# STM32WL33 register map
File version: 1.2
CPU: CM0+ r0p0, little endian, MPU, no FPU, 4 interrupt priority bits
Registers are 32-bit, read-write, reset 0x0 unless marked. A register's access mark holds for its fields unless they carry their own. Offsets are from the block's base; [hi:lo] are bit positions.

## STATUS
Base 0x49000600
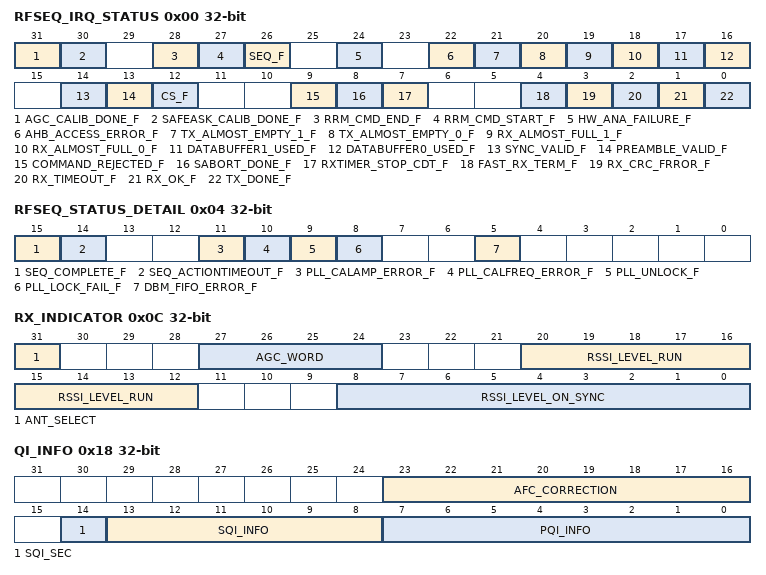
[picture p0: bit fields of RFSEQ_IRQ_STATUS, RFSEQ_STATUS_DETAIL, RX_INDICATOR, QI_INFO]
0x00 RFSEQ_IRQ_STATUS
  [31] AGC_CALIB_DONE_F — Valid RSSI value available in the RSSI_RUNNING bit field flag.
  [30] SAFEASK_CALIB_DONE_F — End of Safe-ASK PA calibration flag.
  [28] RRM_CMD_END_F — RRM-UDRA command list execution ended flag.
  [27] RRM_CMD_START_F — RRM-UDRA command list execution started flag.
  [26] SEQ_F — Sequencer completion flag.
  [24] HW_ANA_FAILURE_F — Analog HW failure flag (PLL lock / unlock error, calibration error)
  [22] AHB_ACCESS_ERROR_F — An AHB transfer issue occurred for one of the AHB masters (RRM, Data Buffer Manager, Sequencer).
  [21] TX_ALMOST_EMPTY_1_F — Data Buffer1 used (read during a TX) up to programmed thresold flag
  [20] TX_ALMOST_EMPTY_0_F — Data Buffer0 used (read during a TX) up to programmed thresold flag
  [19] RX_ALMOST_FULL_1_F — Data Buffer1 used (written during a RX) up to programmed thresold flag
  [18] RX_ALMOST_FULL_0_F — Data Buffer0 used (written during a RX) up to programmed thresold flag
  [17] DATABUFFER1_USED_F — Data Buffer 1 fully read in TX or fully written in RX flag
  [16] DATABUFFER0_USED_F — Data Buffer 0 fully read in TX or fully written in RX flag
  [14] SYNC_VALID_F — Valid SYNC word detection flag.
  [13] PREAMBLE_VALID_F — Valid PREAMBLE detection flag.
  [12] CS_F — Carrier Sense (RSSI over threshold) flag
  [9] COMMAND_REJECTED_F — Command rejection flag.
  [8] SABORT_DONE_F — SABORT command treated and done flag
  [7] RXTIMER_STOP_CDT_F — Enable interrupt on RXTIMER_STOP_CDT_F flag
  [4] FAST_RX_TERM_F — Fast RX Termination flag
  [3] RX_CRC_FRROR_F — Reception with CRC error flag
  [2] RX_TIMEOUT_F — Reception timeout flag
  [1] RX_OK_F — Reception ended and OK flag
  [0] TX_DONE_F — Transmission done flag
0x04 RFSEQ_STATUS_DETAIL
  [15] SEQ_COMPLETE_F — The Sequencer has ended the last defined SeqAction properly( NextAction math or null pointer)
  [14] SEQ_ACTIONTIMEOUT_F — The Sequencer has ended because the current SeqAction reached its ActionTimeout.
  [11] PLL_CALAMP_ERROR_F — VCO amplitude calibration error flag
  [10] PLL_CALFREQ_ERROR_F — VCO frequency calibration error flag
  [9] PLL_UNLOCK_F — PLL unlock event flag
  [8] PLL_LOCK_FAIL_F — PLL lock fail status flag
  [5] DBM_FIFO_ERROR_F — Data Buffer Manager internal FIFO overflow/underflow flag.
0x08 RADIO_FSM_INFO ro
  [4:0] RADIO_FSM_STATE — State of the Radio FSM
0x0C RX_INDICATOR ro
  [31] ANT_SELECT — Currently selected antenna
  [27:24] AGC_WORD — AGC word of the received packet.
  [20:12] RSSI_LEVEL_RUN — Continuous level of the output of the measured RSSI value
  [8:0] RSSI_LEVEL_ON_SYNC — RSSI level captured at the end of the SYNC word detection of the received packet.
0x10 RX_INFO_REG ro
  [15:0] RX_PCKTLEN_OUT — Indicates received packet length in bytes:
0x14 RX_CRC_REG ro
  [31:0] RX_CRC_OUT — CRC field of the received packet (read-only info)
0x18 QI_INFO ro
  [23:16] AFC_CORRECTION — AFC value frozen at sync reception.
  [14] SQI_SEC — Indicate if measured SQI refers to SYNC word or secondary SYNC word
  [13:8] SQI_INFO — SYNC Quality Indicator (SQI) value of the received packet.
  [7:0] PQI_INFO — Preamble Quality Indicator (PQI) value of the received packet.
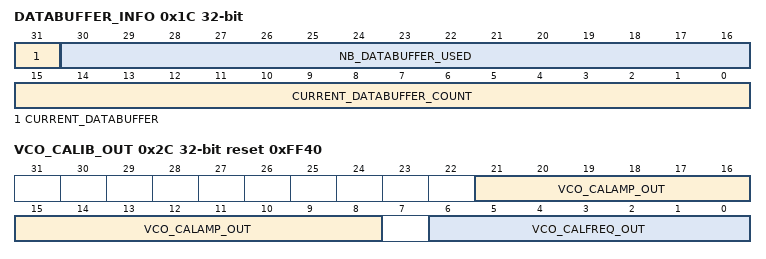
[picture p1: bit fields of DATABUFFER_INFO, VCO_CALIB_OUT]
0x1C DATABUFFER_INFO ro
  [31] CURRENT_DATABUFFER — Indicates which Data Buffer is currently used by the HW
  [30:16] NB_DATABUFFER_USED — Provides the number of data buffers which have been fully used
  [15:0] CURRENT_DATABUFFER_COUNT — Indicates the number of bytes used in the last used DATA BUFFER.
0x20 TIME_CAPTURE ro
  [31:0] TIME_CAPTURE — Interpolated absolute time value captured on specific programmable event through TIME_CAPTURESEL[2:0] bit field.
0x24 IQC_CORRECTION_OUT ro
  [23:0] IQC_CORRECT_OUT — Final correction value output from IQC (compensation engine).
0x28 PA_SAFEASK_OUT ro
  [7:0] PA_CODEMAX — Safe ASK level (provided after a CALIB_SAFEASK command), indicating the maximum PA Power to program before reaching ohmic saturation.
0x2C VCO_CALIB_OUT ro reset 0xFF40
  [21:8] VCO_CALAMP_OUT — VCO amplitude calibration value currently output by the VCO calibration block (and applied on the VCO when ON)
  [6:0] VCO_CALFREQ_OUT — VCO frequency calibration value currently output by the VCO calibration block (and applied on the VCO when ON)
0x30 SEQ_INFO ro
  [4:0] SEQ_FSM_STATE — Current state of the Sequencer
0x34 SEQ_EVENT_STATUS ro
  [31:0] SEQ_EVENT_STATUS — Current value of the seq_event_status used by the Sequencer for next action mask comparison.
